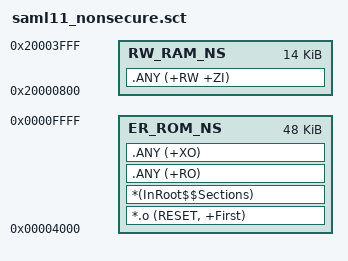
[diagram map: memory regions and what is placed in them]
 ; \brief Keil MDK Scatter-Loading Description File (flash) for ATSAML11E16A
;
; Copyright (c) 2018 Microchip Technology Inc.
;
; \license_start
;
; \page License
;
; SPDX-License-Identifier: Apache-2.0
;
; Licensed under the Apache License, Version 2.0 (the "License");
; you may not use this file except in compliance with the License.
; You may obtain a copy of the License at
;
;   http://www.apache.org/licenses/LICENSE-2.0
;
; Unless required by applicable law or agreed to in writing, software
; distributed under the License is distributed on an "AS IS" BASIS,
; WITHOUT WARRANTIES OR CONDITIONS OF ANY KIND, either express or implied.
; See the License for the specific language governing permissions and
; limitations under the License.
;
; \license_stop

; Memory Spaces Definitions based on Memories Security Attribution:
; BOOTPROT = 0x00
; AS       = 0x40
; ANSC     = 0x20
; RS       = 0x10

LR_ROM_NS 0x00004000 0x0000C000  {   ; load region size_region
  ER_ROM_NS 0x00004000 0x0000C000  { ; load address = execution address
   *.o (RESET, +First)
   *(InRoot$$Sections)

   .ANY (+RO)
   .ANY (+XO)
  }
  RW_RAM_NS 0x20000800 0x00003800  { ; RW data
   .ANY (+RW +ZI)
  }
}
